# AVR32EB14 device description
Architecture: AVR8X; Family: AVREB
Registers are 8-bit, read-write, reset 0x0 unless marked. A register's access mark holds for its fields unless they carry their own. Offsets are from the block's base; [hi:lo] are bit positions; {n}, {i} and the like mark numbered series.

## FUSE — Fuses
Instances: FUSE 0x1050
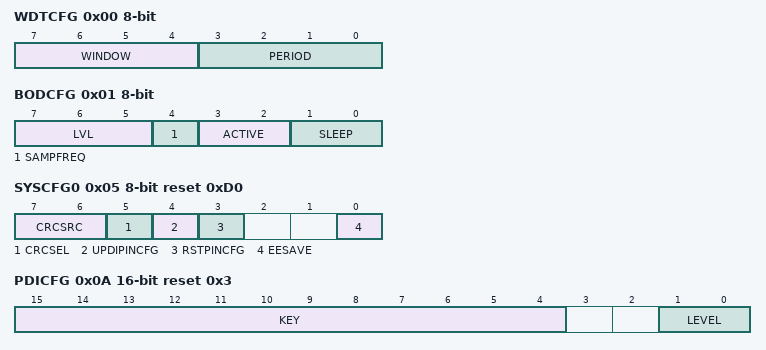
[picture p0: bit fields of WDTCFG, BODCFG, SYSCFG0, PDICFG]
0x00 WDTCFG — Watchdog Configuration
  [7:4] WINDOW — Watchdog Window Timeout Period
    0=OFF (Window mode off); 1=8CLK (8 cycles (8ms)); 2=16CLK (16 cycles (16ms)); 3=32CLK (32 cycles (32ms)); 4=64CLK (64 cycles (64ms)); 5=128CLK (128 cycles (0.128s)); 6=256CLK (256 cycles (0.256s)); 7=512CLK (512 cycles (0.512s)); 8=1KCLK (1K cycles (1.0s)); 9=2KCLK (2K cycles (2.0s)); 10=4KCLK (4K cycles (4.0s)); 11=8KCLK (8K cycles (8.0s))
  [3:0] PERIOD — Watchdog Timeout Period
    0=OFF (Watch-Dog timer Off); 1=8CLK (8 cycles (8ms)); 2=16CLK (16 cycles (16ms)); 3=32CLK (32 cycles (32ms)); 4=64CLK (64 cycles (64ms)); 5=128CLK (128 cycles (0.128s)); 6=256CLK (256 cycles (0.256s)); 7=512CLK (512 cycles (0.512s)); 8=1KCLK (1K cycles (1.0s)); 9=2KCLK (2K cycles (2.0s)); 10=4KCLK (4K cycles (4.0s)); 11=8KCLK (8K cycles (8.0s))
0x01 BODCFG — BOD Configuration
  [7:5] LVL — BOD Level
    0=BODLEVEL0 (BOD Disabled during normal operation); 1=BODLEVEL1 (1.9 V); 2=BODLEVEL2 (2.7 V); 3=BODLEVEL3 (4.5 V)
  [4] SAMPFREQ — BOD Sample Frequency
    0=128HZ (Sampling frequency is 128 Hz); 1=32HZ (Sample frequency is 32 Hz)
  [3:2] ACTIVE — BOD Operation in Active Mode
    0=DISABLE (Disabled); 1=ENABLED (Enabled in continuous mode); 2=SAMPLED (Enabled in sampled mode); 3=ENABLEWAIT (Enabled in continuous mode. Execution halted at wake-up until BOD is running)
  [1:0] SLEEP — BOD Operation in Sleep Mode
    0=DISABLE (Disabled); 1=ENABLE (Enabled in continuous mode); 2=SAMPLE (Enabled in sampled mode)
0x02 OSCCFG — Oscillator Configuration
  [3] OSCHFFRQ — High-frequency Oscillator Frequency
    0=20M (OSCHF running at 20 MHz); 1=16M (OSCHF running at 16 MHz)
0x05 SYSCFG0 reset 0xD0 — System Configuration 0
  [7:6] CRCSRC — CRC Source
    0=FLASH (CRC of full Flash (boot, application code and application data)); 1=BOOT (CRC of boot section); 2=BOOTAPP (CRC of application code and boot sections); 3=NOCRC
  [5] CRCSEL — CRC Select
    0=CRC16 (Enable CRC16); 1=CRC32 (Enable CRC32)
  [4] UPDIPINCFG — UPDI Pin Configuration
    0=GPIO (PF7 Configured as GPIO pin); 1=UPDI (PF7 Configured as UPDI pin)
  [3] RSTPINCFG — Reset Pin Configuration
    0=NONE (No External Reset); 1=RESET (PF6 configured as RESET pin)
  [0] EESAVE — EEPROM Save
    0=DISABLE (EEPROM content is erased during chip erase); 1=ENABLE (EEPROM content is preserved during chip erase)
0x06 SYSCFG1 reset 0x7 — System Configuration 1
  [2:0] SUT — Startup Time
    0=0MS; 1=1MS; 2=2MS; 3=4MS; 4=8MS; 5=16MS; 6=32MS; 7=64MS
0x07 CODESIZE — Code Section Size
0x08 BOOTSIZE — Boot Section Size
0x0A PDICFG 16-bit reset 0x3 — Programming and Debugging Interface Configuration
  [15:4] KEY — NVM Protection Activation Key
    0=NOTACT (Not Active); 0xB45=NVMACT (NVM Protection Active)
  [1:0] LEVEL — Protection Level
    2=NVMACCDIS (NVM Access through UPDI disabled); 3=BASIC (UPDI and UPDI pins working normally)

## GPR — General Purpose Registers
Instances: GPR 0x001C
{0x0+i} GPR{i} reset not defined (i=0..3) — General Purpose Register {i}

## LOCK — Lockbits
Instances: LOCK 0x1040
0x00 KEY 32-bit reset 0x5CC5C55C — Lock Key Bits
  [31:0] KEY — Lock Key
    0x5CC5C55C=NOLOCK (No locks); 0xA33A3AA3=RWLOCK (Read and write lock)

## NVMCTRL — Non-volatile Memory Controller
Instances: NVMCTRL 0x1000
0x00 CTRLA — Control A
  [6:0] CMD — Command
    0=NOCMD (No Command); 1=NOOP (No Operation); 4=FLPW (Flash Page Write); 5=FLPERW (Flash Page Erase and Write); 8=FLPER (Flash Page Erase); 9=FLMPER2 (Flash 2-page erase enable); 10=FLMPER4 (Flash 4-page erase enable); 11=FLMPER8 (Flash 8-page erase enable); 12=FLMPER16 (Flash 16-page erase enable); 13=FLMPER32 (Flash 32-page erase enable); 15=FLPBCLR (Flash Page Buffer Clear); 20=EEPW (EEPROM Page Write); 21=EEPERW (EEPROM Page Erase and Write); 23=EEPER (EEPROM Page Erase); 31=EEPBCLR (EEPROM Page Buffer Clear); 32=CHER (Chip Erase Command (UPDI only)); 48=EECHER (EEPROM Erase Command (UPDI only))
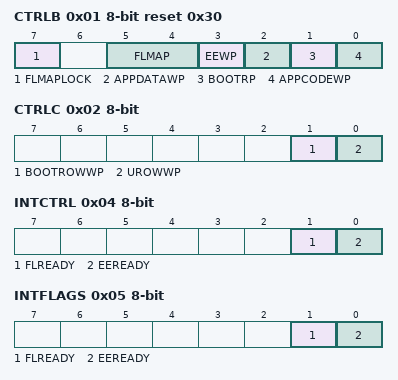
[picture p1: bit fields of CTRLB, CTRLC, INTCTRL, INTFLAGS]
0x01 CTRLB reset 0x30 — Control B
  [7] FLMAPLOCK — Flash Mapping Lock
  [5:4] FLMAP — Flash Mapping in Data space
    0=SECTION0 (Flash section 0, 0 - 32KB); 1=SECTION1 (Flash section 1, 32 - 64KB); 2=SECTION2 (Flash section 2, 64 - 96KB); 3=SECTION3 (Flash section 3, 96 - 128KB)
  [3] EEWP — EEPROM Write Protect
  [2] APPDATAWP — Application Data Write Protect
  [1] BOOTRP — Boot Read Protect
  [0] APPCODEWP — Application Code Write Protect
0x02 CTRLC — Control C
  [1] BOOTROWWP — Boot Row Write Protect
  [0] UROWWP — User Row Write Protect
0x04 INTCTRL — Interrupt Control
  [1] FLREADY — Flash Ready
  [0] EEREADY — EEPROM Ready
0x05 INTFLAGS — Interrupt Flags
  [1] FLREADY — Flash Ready
  [0] EEREADY — EEPROM Ready
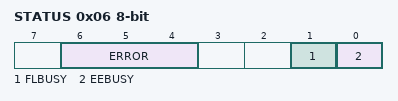
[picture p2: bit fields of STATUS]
0x06 STATUS
  [6:4] ERROR — Write error
    0=NOERROR; 2=WRITEPROTECT (Attempt to program write protected area); 3=CMDCOLLISION (Selecting new write command while write command already seleted); 4=WRONGSECTION (Address cannot be written with selected command)
  [1] FLBUSY ro — Flash busy
  [0] EEBUSY ro — EEPROM busy
0x08 DATA 16-bit
0x0C ADDR 32-bit — Address
  [23:0] ADDR
